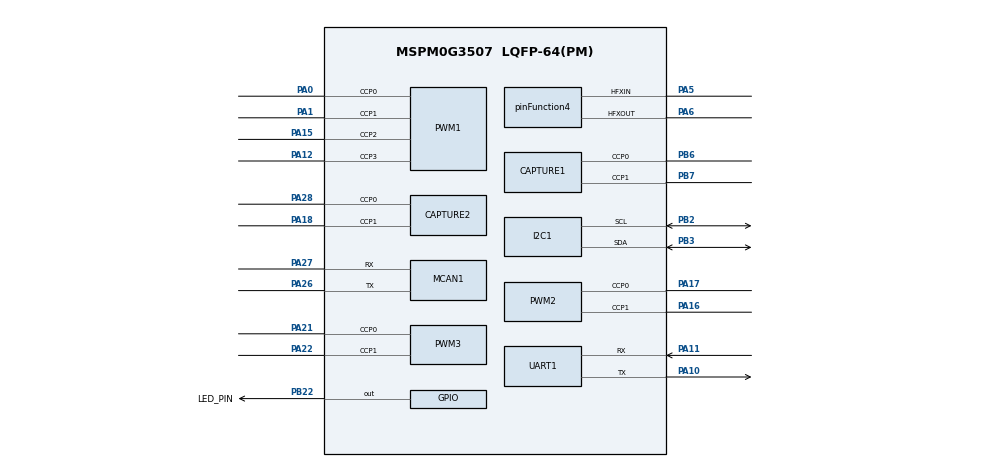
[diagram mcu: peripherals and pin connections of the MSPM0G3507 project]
/**
 * These arguments were used when this file was generated. They will be automatically applied on subsequent loads
 * via the GUI or CLI. Run CLI with '--help' for additional information on how to override these arguments.
 * @cliArgs --device "MSPM0G350X" --part "Default" --package "LQFP-64(PM)" --product "mspm0_sdk@2.10.00.04"
 * @v2CliArgs --device "MSPM0G3507" --package "LQFP-64(PM)" --product "mspm0_sdk@2.10.00.04"
 * @versions {"tool":"1.26.2+4477"}
 */

/**
 * Import the modules used in this configuration.
 */
const CAPTURE       = scripting.addModule("/ti/driverlib/CAPTURE", {}, false);
const CAPTURE1      = CAPTURE.addInstance();
const CAPTURE2      = CAPTURE.addInstance();
const GPIO          = scripting.addModule("/ti/driverlib/GPIO", {}, false);
const GPIO1         = GPIO.addInstance();
const I2C           = scripting.addModule("/ti/driverlib/I2C", {}, false);
const I2C1          = I2C.addInstance();
const MCAN          = scripting.addModule("/ti/driverlib/MCAN", {}, false);
const MCAN1         = MCAN.addInstance();
const PWM           = scripting.addModule("/ti/driverlib/PWM", {}, false);
const PWM1          = PWM.addInstance();
const PWM2          = PWM.addInstance();
const PWM3          = PWM.addInstance();
const SYSCTL        = scripting.addModule("/ti/driverlib/SYSCTL");
const SYSTICK       = scripting.addModule("/ti/driverlib/SYSTICK");
const UART          = scripting.addModule("/ti/driverlib/UART", {}, false);
const UART1         = UART.addInstance();
const ProjectConfig = scripting.addModule("/ti/project_config/ProjectConfig");

/**
 * Write custom configuration values to the imported modules.
 */
const divider9       = system.clockTree["UDIV"];
divider9.divideValue = 2;

const multiplier2         = system.clockTree["PLL_QDIV"];
multiplier2.multiplyValue = 4;

const mux4       = system.clockTree["EXHFMUX"];
mux4.inputSelect = "EXHFMUX_XTAL";

const mux5       = system.clockTree["EXLFMUX"];
mux5.inputSelect = "EXLFMUX_XTAL";

const mux8       = system.clockTree["HSCLKMUX"];
mux8.inputSelect = "HSCLKMUX_SYSPLL0";

const mux9       = system.clockTree["LFXTMUX"];
mux9.inputSelect = "LFXTMUX_TRUE";

const mux10       = system.clockTree["MFPCLKMUX"];
mux10.inputSelect = "MFPCLKMUX_HFCLK";

const mux12       = system.clockTree["SYSPLLMUX"];
mux12.inputSelect = "zSYSPLLMUX_HFCLK";

const pinFunction4                        = system.clockTree["HFXT"];
pinFunction4.inputFreq                    = 40;
pinFunction4.enable                       = true;
pinFunction4.HFXTStartup                  = 10;
pinFunction4.peripheral.$assign           = "SYSCTL";
pinFunction4.peripheral.hfxInPin.$assign  = "PA5";
pinFunction4.peripheral.hfxOutPin.$assign = "PA6";

const pinFunction6     = system.clockTree["LFXT"];
pinFunction6.inputFreq = 32.768;
pinFunction6.enable    = true;

CAPTURE1.timerClkPrescale                   = 40;
CAPTURE1.timerStartTimer                    = true;
CAPTURE1.captMode                           = "EDGE_TIME_UP";
CAPTURE1.captureInputMode                   = "multi";
CAPTURE1.ccIndexMulti                       = [0,1];
CAPTURE1.multi_countMode                    = "DL_TIMER_COUNT_MODE_UP";
CAPTURE1.multi_cvae                         = "DL_TIMER_COUNT_AFTER_EN_ZERO";
CAPTURE1.multi_ch1_input_filter             = true;
CAPTURE1.multi_ch1_filteringMode            = "VOTING";
CAPTURE1.multi_ch0_input_filter             = true;
CAPTURE1.multi_ch0_filteringMode            = "VOTING";
CAPTURE1.multi_countRep                     = "DL_TIMER_REPEAT_MODE_ENABLED";
CAPTURE1.$name                              = "FFRONT_IN";
CAPTURE1.peripheral.$assign                 = "TIMG8";
CAPTURE1.peripheral.ccp0Pin.$assign         = "PB6";
CAPTURE1.peripheral.ccp1Pin.$assign         = "PB7";
CAPTURE1.ccp0PinConfig.hideOutputInversion  = scripting.forceWrite(false);
CAPTURE1.ccp0PinConfig.onlyInternalResistor = scripting.forceWrite(false);
CAPTURE1.ccp0PinConfig.passedPeripheralType = scripting.forceWrite("Digital");
CAPTURE1.ccp0PinConfig.$name                = "ti_driverlib_gpio_GPIOPinGeneric12";
CAPTURE1.ccp1PinConfig.hideOutputInversion  = scripting.forceWrite(false);
CAPTURE1.ccp1PinConfig.onlyInternalResistor = scripting.forceWrite(false);
CAPTURE1.ccp1PinConfig.passedPeripheralType = scripting.forceWrite("Digital");
CAPTURE1.ccp1PinConfig.$name                = "ti_driverlib_gpio_GPIOPinGeneric13";

const Board = scripting.addModule("/ti/driverlib/Board", {}, false);

CAPTURE2.timerStartTimer                    = true;
CAPTURE2.captMode                           = "EDGE_TIME_UP";
CAPTURE2.captureInputMode                   = "multi";
CAPTURE2.ccIndexMulti                       = [0,1];
CAPTURE2.multi_countMode                    = "DL_TIMER_COUNT_MODE_UP";
CAPTURE2.multi_cvae                         = "DL_TIMER_COUNT_AFTER_EN_ZERO";
CAPTURE2.multi_ch1_input_filter             = true;
CAPTURE2.multi_ch1_filteringMode            = "VOTING";
CAPTURE2.multi_ch0_input_filter             = true;
CAPTURE2.multi_ch0_filteringMode            = "VOTING";
CAPTURE2.timerClkPrescale                   = 80;
CAPTURE2.multi_countRep                     = "DL_TIMER_REPEAT_MODE_ENABLED";
CAPTURE2.$name                              = "REAR_IN";
CAPTURE2.peripheral.$assign                 = "TIMG7";
CAPTURE2.peripheral.ccp0Pin.$assign         = "PA28";
CAPTURE2.peripheral.ccp1Pin.$assign         = "PA18";
CAPTURE2.ccp0PinConfig.hideOutputInversion  = scripting.forceWrite(false);
CAPTURE2.ccp0PinConfig.onlyInternalResistor = scripting.forceWrite(false);
CAPTURE2.ccp0PinConfig.passedPeripheralType = scripting.forceWrite("Digital");
CAPTURE2.ccp0PinConfig.$name                = "ti_driverlib_gpio_GPIOPinGeneric14";
CAPTURE2.ccp1PinConfig.hideOutputInversion  = scripting.forceWrite(false);
CAPTURE2.ccp1PinConfig.onlyInternalResistor = scripting.forceWrite(false);
CAPTURE2.ccp1PinConfig.passedPeripheralType = scripting.forceWrite("Digital");
CAPTURE2.ccp1PinConfig.$name                = "ti_driverlib_gpio_GPIOPinGeneric15";

GPIO1.$name                              = "LED";
GPIO1.port                               = "PORTB";
GPIO1.associatedPins[0].$name            = "LED_PIN";
GPIO1.associatedPins[0].assignedPin      = "22";
GPIO1.associatedPins[0].internalResistor = "PULL_UP";
GPIO1.associatedPins[0].pin.$assign      = "PB22";

I2C1.basicEnableController             = true;
I2C1.basicControllerStandardBusSpeed   = "Fast";
I2C1.$name                             = "I2C_OLED";
I2C1.peripheral.sdaPin.$assign         = "PB3";
I2C1.peripheral.sclPin.$assign         = "PB2";
I2C1.sdaPinConfig.hideOutputInversion  = scripting.forceWrite(false);
I2C1.sdaPinConfig.onlyInternalResistor = scripting.forceWrite(false);
I2C1.sdaPinConfig.passedPeripheralType = scripting.forceWrite("Digital");
I2C1.sdaPinConfig.$name                = "ti_driverlib_gpio_GPIOPinGeneric16";
I2C1.sclPinConfig.hideOutputInversion  = scripting.forceWrite(false);
I2C1.sclPinConfig.onlyInternalResistor = scripting.forceWrite(false);
I2C1.sclPinConfig.passedPeripheralType = scripting.forceWrite("Digital");
I2C1.sclPinConfig.$name                = "ti_driverlib_gpio_GPIOPinGeneric17";

MCAN1.$name                    = "MCAN0";
MCAN1.fdMode                   = false;
MCAN1.enableInterrupt          = true;
MCAN1.spPercent                = 85;
MCAN1.desiredDataRate          = 0;
MCAN1.stdFiltType              = "10";
MCAN1.extFiltType              = "10";
MCAN1.txBufElemSize            = "DL_MCAN_ELEM_SIZE_8BYTES";
MCAN1.txBufNum                 = 8;
MCAN1.rxFIFO0size              = 8;
MCAN1.rxFIFO1OpMode            = "1";
MCAN1.rxFIFO0ElemSize          = "DL_MCAN_ELEM_SIZE_8BYTES";
MCAN1.rxFIFO1ElemSize          = "DL_MCAN_ELEM_SIZE_8BYTES";
MCAN1.interruptFlags           = ["DL_MCAN_INTERRUPT_RF0N"];
MCAN1.extFiltElem              = "001";
MCAN1.stdFiltElem              = "001";
MCAN1.interruptLine            = ["DL_MCAN_INTR_LINE_NUM_0"];
MCAN1.interruptLine0Flag       = ["DL_MCAN_INTERRUPT_RF0N"];
MCAN1.m0interrupts             = ["DL_MCAN_MSP_INTERRUPT_LINE0"];
MCAN1.txFIFOSize               = 8;
MCAN1.desiredNomRate           = 1000;
MCAN1.peripheral.rxPin.$assign = "PA27";
MCAN1.peripheral.txPin.$assign = "PA26";
MCAN1.txPinConfig.$name        = "ti_driverlib_gpio_GPIOPinGeneric0";
MCAN1.rxPinConfig.$name        = "ti_driverlib_gpio_GPIOPinGeneric1";

PWM1.clockPrescale                      = 80;
PWM1.timerStartTimer                    = true;
PWM1.$name                              = "FRONT_OUT";
PWM1.enableShadowLoad                   = true;
PWM1.ccIndex                            = [0,1,2,3];
PWM1.timerCount                         = 5000;
PWM1.PWM_CHANNEL_0.$name                = "ti_driverlib_pwm_PWMTimerCC0";
PWM1.PWM_CHANNEL_0.shadowUpdateMode     = "ZERO_EVT";
PWM1.PWM_CHANNEL_1.$name                = "ti_driverlib_pwm_PWMTimerCC1";
PWM1.PWM_CHANNEL_1.shadowUpdateMode     = "ZERO_EVT";
PWM1.ccp0PinConfig.direction            = scripting.forceWrite("OUTPUT");
PWM1.ccp0PinConfig.hideOutputInversion  = scripting.forceWrite(false);
PWM1.ccp0PinConfig.onlyInternalResistor = scripting.forceWrite(false);
PWM1.ccp0PinConfig.passedPeripheralType = scripting.forceWrite("Digital");
PWM1.ccp0PinConfig.$name                = "ti_driverlib_gpio_GPIOPinGeneric4";
PWM1.ccp0PinConfig.internalResistor     = "PULL_UP";
PWM1.ccp1PinConfig.direction            = scripting.forceWrite("OUTPUT");
PWM1.ccp1PinConfig.hideOutputInversion  = scripting.forceWrite(false);
PWM1.ccp1PinConfig.onlyInternalResistor = scripting.forceWrite(false);
PWM1.ccp1PinConfig.passedPeripheralType = scripting.forceWrite("Digital");
PWM1.ccp1PinConfig.$name                = "ti_driverlib_gpio_GPIOPinGeneric5";
PWM1.ccp1PinConfig.internalResistor     = "PULL_UP";
PWM1.peripheral.ccp0Pin.$assign         = "PA0";
PWM1.peripheral.ccp1Pin.$assign         = "PA1";
PWM1.peripheral.ccp2Pin.$assign         = "PA15";
PWM1.peripheral.ccp3Pin.$assign         = "PA12";
PWM1.PWM_CHANNEL_2.$name                = "ti_driverlib_pwm_PWMTimerCC2";
PWM1.PWM_CHANNEL_2.shadowUpdateMode     = "ZERO_EVT";
PWM1.PWM_CHANNEL_3.$name                = "ti_driverlib_pwm_PWMTimerCC3";
PWM1.PWM_CHANNEL_3.shadowUpdateMode     = "ZERO_EVT";
PWM1.ccp2PinConfig.$name                = "ti_driverlib_gpio_GPIOPinGeneric6";
PWM1.ccp2PinConfig.internalResistor     = "PULL_UP";
PWM1.ccp3PinConfig.$name                = "ti_driverlib_gpio_GPIOPinGeneric7";

PWM2.clockPrescale                      = 80;
PWM2.timerStartTimer                    = true;
PWM2.$name                              = "RL_OUT";
PWM2.enableShadowLoad                   = true;
PWM2.timerCount                         = 5000;
PWM2.peripheral.$assign                 = "TIMA1";
PWM2.peripheral.ccp0Pin.$assign         = "PA17";
PWM2.peripheral.ccp1Pin.$assign         = "PA16";
PWM2.PWM_CHANNEL_0.$name                = "ti_driverlib_pwm_PWMTimerCC4";
PWM2.PWM_CHANNEL_1.$name                = "ti_driverlib_pwm_PWMTimerCC5";
PWM2.PWM_CHANNEL_1.shadowUpdateMode     = "ZERO_EVT";
PWM2.ccp0PinConfig.$name                = "ti_driverlib_gpio_GPIOPinGeneric8";
PWM2.ccp0PinConfig.direction            = scripting.forceWrite("OUTPUT");
PWM2.ccp0PinConfig.hideOutputInversion  = scripting.forceWrite(false);
PWM2.ccp0PinConfig.onlyInternalResistor = scripting.forceWrite(false);
PWM2.ccp0PinConfig.passedPeripheralType = scripting.forceWrite("Digital");
PWM2.ccp1PinConfig.$name                = "ti_driverlib_gpio_GPIOPinGeneric9";
PWM2.ccp1PinConfig.direction            = scripting.forceWrite("OUTPUT");
PWM2.ccp1PinConfig.hideOutputInversion  = scripting.forceWrite(false);
PWM2.ccp1PinConfig.onlyInternalResistor = scripting.forceWrite(false);
PWM2.ccp1PinConfig.passedPeripheralType = scripting.forceWrite("Digital");

PWM3.$name                              = "RR_OUT";
PWM3.timerStartTimer                    = true;
PWM3.clockPrescale                      = 80;
PWM3.enableShadowLoad                   = true;
PWM3.timerCount                         = 5000;
PWM3.peripheral.$assign                 = "TIMG6";
PWM3.peripheral.ccp0Pin.$assign         = "PA21";
PWM3.peripheral.ccp1Pin.$assign         = "PA22";
PWM3.PWM_CHANNEL_0.$name                = "ti_driverlib_pwm_PWMTimerCC6";
PWM3.PWM_CHANNEL_0.shadowUpdateMode     = "ZERO_EVT";
PWM3.PWM_CHANNEL_1.$name                = "ti_driverlib_pwm_PWMTimerCC7";
PWM3.PWM_CHANNEL_1.shadowUpdateMode     = "ZERO_EVT";
PWM3.ccp0PinConfig.$name                = "ti_driverlib_gpio_GPIOPinGeneric10";
PWM3.ccp0PinConfig.direction            = scripting.forceWrite("OUTPUT");
PWM3.ccp0PinConfig.hideOutputInversion  = scripting.forceWrite(false);
PWM3.ccp0PinConfig.onlyInternalResistor = scripting.forceWrite(false);
PWM3.ccp0PinConfig.passedPeripheralType = scripting.forceWrite("Digital");
PWM3.ccp1PinConfig.$name                = "ti_driverlib_gpio_GPIOPinGeneric11";
PWM3.ccp1PinConfig.direction            = scripting.forceWrite("OUTPUT");
PWM3.ccp1PinConfig.hideOutputInversion  = scripting.forceWrite(false);
PWM3.ccp1PinConfig.onlyInternalResistor = scripting.forceWrite(false);
PWM3.ccp1PinConfig.passedPeripheralType = scripting.forceWrite("Digital");

SYSCTL.forceDefaultClkConfig = true;
SYSCTL.clockTreeEn           = true;

SYSTICK.periodEnable    = true;
SYSTICK.period          = 80000;
SYSTICK.interruptEnable = true;
SYSTICK.systickEnable   = true;

UART1.$name                          = "UART_0";
UART1.targetBaudRate                 = 115200;
UART1.calculatedBaudRate             = 1;
UART1.enabledDMATXTriggers           = "DL_UART_DMA_INTERRUPT_TX";
UART1.enabledDMARXTriggers           = "DL_UART_DMA_INTERRUPT_RX";
UART1.rxFifoThreshold                = "DL_UART_RX_FIFO_LEVEL_ONE_ENTRY";
UART1.enableFIFO                     = true;
UART1.rxTimeoutValue                 = 10;
UART1.enabledInterrupts              = ["DMA_DONE_RX","DMA_DONE_TX","EOT_DONE"];
UART1.peripheral.rxPin.$assign       = "PA11";
UART1.peripheral.txPin.$assign       = "PA10";
UART1.txPinConfig.$name              = "ti_driverlib_gpio_GPIOPinGeneric2";
UART1.rxPinConfig.$name              = "ti_driverlib_gpio_GPIOPinGeneric3";
UART1.DMA_CHANNEL_TX.$name           = "DMA_CH0";
UART1.DMA_CHANNEL_TX.addressMode     = "b2f";
UART1.DMA_CHANNEL_TX.srcLength       = "BYTE";
UART1.DMA_CHANNEL_TX.dstLength       = "BYTE";
UART1.DMA_CHANNEL_TX.enableInterrupt = true;
UART1.DMA_CHANNEL_RX.$name           = "DMA_CH1";
UART1.DMA_CHANNEL_RX.addressMode     = "f2b";
UART1.DMA_CHANNEL_RX.srcLength       = "BYTE";
UART1.DMA_CHANNEL_RX.dstLength       = "BYTE";
UART1.DMA_CHANNEL_RX.transferSize    = 4096;
UART1.DMA_CHANNEL_RX.enableInterrupt = true;

ProjectConfig.genLibCMSIS = true;

/**
 * Pinmux solution for unlocked pins/peripherals. This ensures that minor changes to the automatic solver in a future
 * version of the tool will not impact the pinmux you originally saw.  These lines can be completely deleted in order to
 * re-solve from scratch.
 */
pinFunction6.peripheral.$suggestSolution           = "SYSCTL";
pinFunction6.peripheral.lfxInPin.$suggestSolution  = "PA3";
pinFunction6.peripheral.lfxOutPin.$suggestSolution = "PA4";
Board.peripheral.$suggestSolution                  = "DEBUGSS";
Board.peripheral.swclkPin.$suggestSolution         = "PA20";
Board.peripheral.swdioPin.$suggestSolution         = "PA19";
I2C1.peripheral.$suggestSolution                   = "I2C1";
MCAN1.peripheral.$suggestSolution                  = "CANFD0";
PWM1.peripheral.$suggestSolution                   = "TIMA0";
UART1.peripheral.$suggestSolution                  = "UART0";
UART1.DMA_CHANNEL_TX.peripheral.$suggestSolution   = "DMA_CH1";
UART1.DMA_CHANNEL_RX.peripheral.$suggestSolution   = "DMA_CH0";
